# MB9BF46xx register map
File version: 1.0
CPU: 
Registers are 8-bit, read-write, reset 0x0 unless marked. A register's access mark holds for its fields unless they carry their own. Offsets are from the block's base; [hi:lo] are bit positions; {n}, {i} and the like mark numbered series; 'fields as' and 'values as' point back to an identical list.

## BTIOSEL03 — peripheral BTIOSEL03
Base 0x40025100
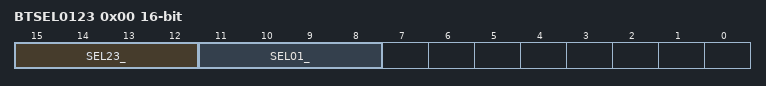
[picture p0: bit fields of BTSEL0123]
0x00 BTSEL0123 16-bit
  [15:12] SEL23_, [11:8] SEL01_

## BTIOSEL47 — peripheral BTIOSEL47
Base 0x40025300
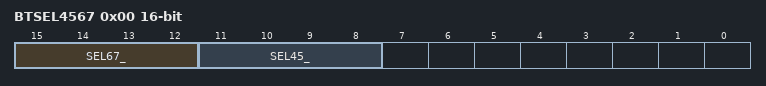
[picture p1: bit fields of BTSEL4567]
0x00 BTSEL4567 16-bit
  [15:12] SEL67_, [11:8] SEL45_

## BTIOSEL8B — peripheral BTIOSEL8B
Base 0x40025500
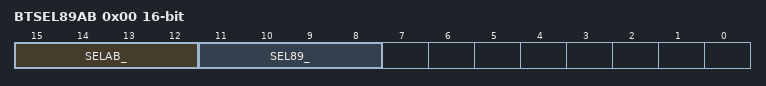
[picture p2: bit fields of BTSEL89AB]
0x00 BTSEL89AB 16-bit
  [15:12] SELAB_, [11:8] SEL89_

## BTIOSELCF — peripheral BTIOSELCF
Base 0x40025700
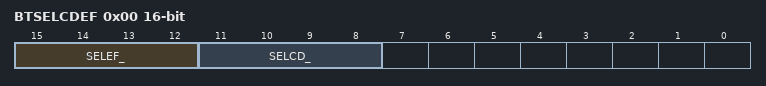
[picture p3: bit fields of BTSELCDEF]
0x00 BTSELCDEF 16-bit
  [15:12] SELEF_, [11:8] SELCD_

## SBSSR — peripheral SBSSR
Base 0x40025F00
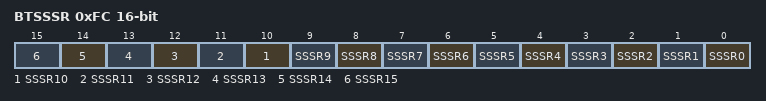
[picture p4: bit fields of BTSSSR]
0xFC BTSSSR 16-bit wo reset not defined
  [n] SSSR{n} (n=0..15)

## BT0 — peripheral BT0
Base 0x40025000
Same registers: BT1 0x40025040, BT2 0x40025080, BT3 0x400250C0, BT4 0x40025200, BT5 0x40025240, BT6 0x40025280, BT7 0x400252C0, BT8 0x40025400, BT9 0x40025440, BT10 0x40025480, BT11 0x400254C0, BT12 0x40025600, BT13 0x40025640, BT14 0x40025680, BT15 0x400256C0
0x00 PWM_PCSR 16-bit reset not defined (PWM view)
0x00 PPG_PRLL 16-bit reset not defined (PPG view)
0x00 RT_PCSR 16-bit reset not defined (RT view)
0x04 PWM_PDUT 16-bit reset not defined (PWM view)
0x04 PPG_PRLH 16-bit reset not defined (PPG view)
0x04 PWC_DTBF 16-bit ro (PWC view)
0x08 PWM_TMR 16-bit ro (PWM view)
0x08 PPG_TMR 16-bit ro (PPG view)
0x08 RT_TMR 16-bit ro reset not defined (RT view)
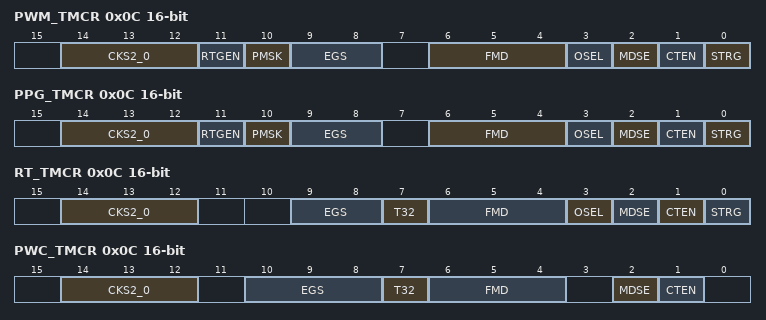
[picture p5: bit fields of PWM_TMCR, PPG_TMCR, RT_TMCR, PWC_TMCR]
0x0C PWM_TMCR 16-bit (PWM view)
  [14:12] CKS2_0, [11] RTGEN, [10] PMSK, [9:8] EGS, [6:4] FMD, [3] OSEL, [2] MDSE, [1] CTEN, [0] STRG
0x0C PPG_TMCR 16-bit (PPG view)
  fields as PWM_TMCR
0x0C RT_TMCR 16-bit (RT view)
  [14:12] CKS2_0, [9:8] EGS, [7] T32, [6:4] FMD, [3] OSEL, [2] MDSE, [1] CTEN, [0] STRG
0x0C PWC_TMCR 16-bit (PWC view)
  [14:12] CKS2_0, [10:8] EGS, [7] T32, [6:4] FMD, [2] MDSE, [1] CTEN
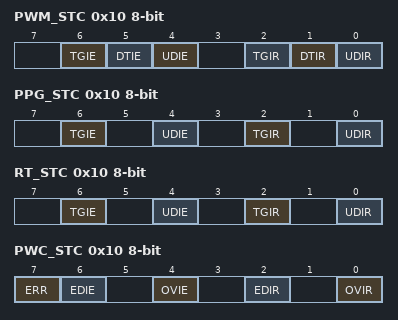
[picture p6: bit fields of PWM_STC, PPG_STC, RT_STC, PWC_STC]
0x10 PWM_STC (PWM view)
  [6] TGIE, [5] DTIE, [4] UDIE, [2] TGIR, [1] DTIR, [0] UDIR
0x10 PPG_STC (PPG view)
  [6] TGIE, [4] UDIE, [2] TGIR, [0] UDIR
0x10 RT_STC (RT view)
  [6] TGIE, [4] UDIE, [2] TGIR, [0] UDIR
0x10 PWC_STC (PWC view)
  [7] ERR ro, [6] EDIE, [4] OVIE, [2] EDIR ro, [0] OVIR
0x11 PWM_TMCR2 (PWM view)
  [0] CKS3
0x11 PPG_TMCR2 (reset mask 0x1) (PPG view)
  [1] CKS3
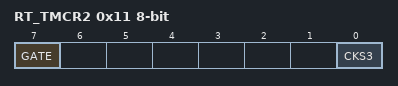
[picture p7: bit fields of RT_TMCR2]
0x11 RT_TMCR2 (RT view)
  [7] GATE, [0] CKS3
0x11 PWC_TMCR2 (PWC view)
  [0] CKS3

## QPRC0 — peripheral QPRC0
Base 0x40026000
Same registers: QPRC1 0x40026040, QPRC2 0x40026080, QPRC3 0x400260C0
0x00 QPCR 16-bit
0x04 QRCR 16-bit
0x08 QPCCR 16-bit
0x0C QPRCR 16-bit
0x10 QMPR 16-bit reset 0xFFFF
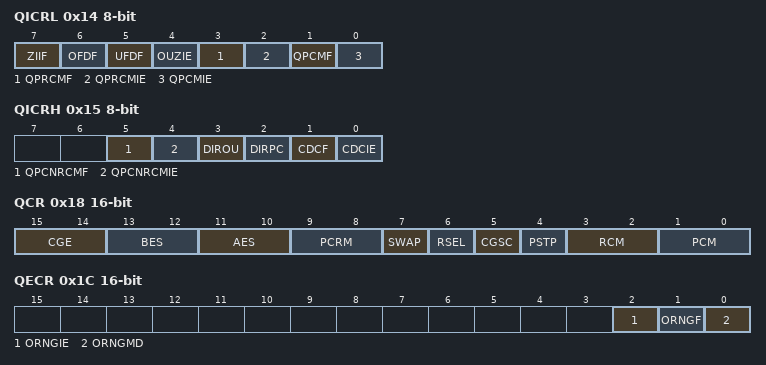
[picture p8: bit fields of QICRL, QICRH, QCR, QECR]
0x14 QICRL
  [7] ZIIF, [6] OFDF, [5] UFDF, [4] OUZIE, [3] QPRCMF, [2] QPRCMIE, [1] QPCMF, [0] QPCMIE
0x15 QICRH
  [5] QPCNRCMF, [4] QPCNRCMIE, [3] DIROU ro, [2] DIRPC ro, [1] CDCF, [0] CDCIE
0x18 QCR 16-bit
  [15:14] CGE, [13:12] BES, [11:10] AES, [9:8] PCRM, [7] SWAP, [6] RSEL, [5] CGSC, [4] PSTP, [3:2] RCM, [1:0] PCM
0x1C QECR 16-bit
  [2] ORNGIE, [1] ORNGF, [0] ORNGMD
0x3C QRCRR 16-bit
0x3E QPCRR 16-bit

## QPRC0_NF — peripheral QPRC0_NF
Base 0x40026100
Same registers: QPRC1_NF 0x40026110, QPRC2_NF 0x40026120, QPRC3_NF 0x40026130
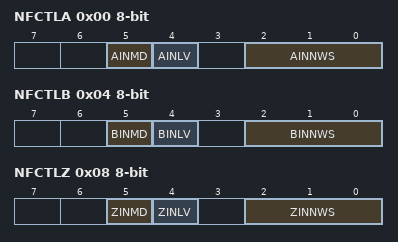
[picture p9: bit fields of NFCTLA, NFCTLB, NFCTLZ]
0x00 NFCTLA
  [5] AINMD, [4] AINLV, [2:0] AINNWS
0x04 NFCTLB
  [5] BINMD, [4] BINLV, [2:0] BINNWS
0x08 NFCTLZ
  [5] ZINMD, [4] ZINLV, [2:0] ZINNWS

## ADC0 — peripheral ADC0
Base 0x40027000
Same registers: ADC1 0x40027100, ADC2 0x40027200
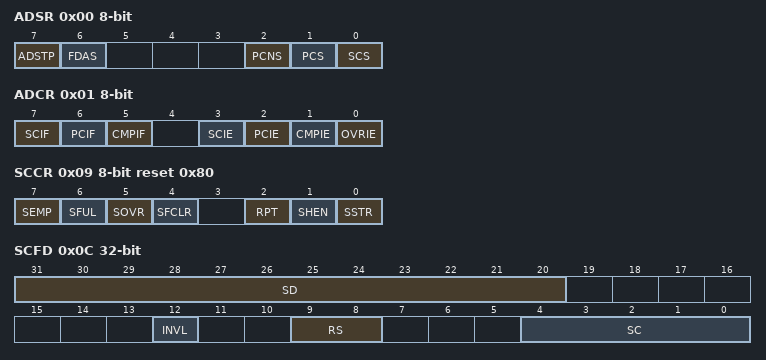
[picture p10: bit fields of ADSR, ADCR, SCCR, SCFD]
0x00 ADSR
  [7] ADSTP, [6] FDAS, [2] PCNS, [1] PCS, [0] SCS
0x01 ADCR
  [7] SCIF, [6] PCIF, [5] CMPIF, [3] SCIE, [2] PCIE, [1] CMPIE, [0] OVRIE
0x08 SFNS
  [3:0] SFS
0x09 SCCR reset 0x80
  [7] SEMP ro, [6] SFUL ro, [5] SOVR, [4] SFCLR, [2] RPT, [1] SHEN, [0] SSTR
0x0C SCFD 32-bit ro
  [31:20] SD, [12] INVL, [9:8] RS, [4:0] SC
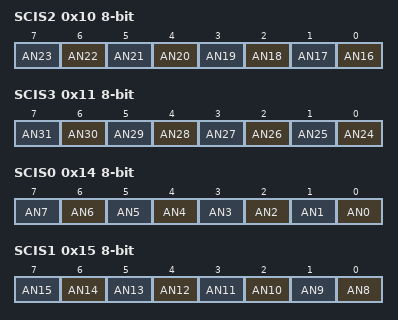
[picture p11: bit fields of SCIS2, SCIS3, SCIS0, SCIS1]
0x10 SCIS2
  [n-16] AN{n} (n=16..23)
0x11 SCIS3
  [n-24] AN{n} (n=24..31)
0x14 SCIS0
  [n] AN{n} (n=0..7)
0x15 SCIS1
  [n-8] AN{n} (n=8..15)
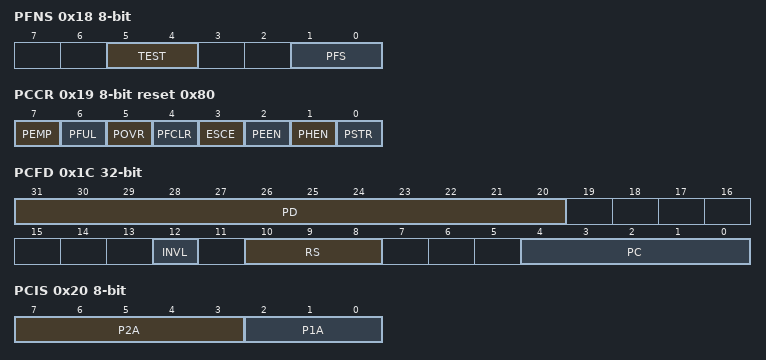
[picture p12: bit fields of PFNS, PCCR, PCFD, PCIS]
0x18 PFNS
  [5:4] TEST ro, [1:0] PFS
0x19 PCCR reset 0x80
  [7] PEMP ro, [6] PFUL ro, [5] POVR, [4] PFCLR, [3] ESCE, [2] PEEN, [1] PHEN, [0] PSTR
0x1C PCFD 32-bit ro
  [31:20] PD, [12] INVL, [10:8] RS, [4:0] PC
0x20 PCIS
  [7:3] P2A, [2:0] P1A
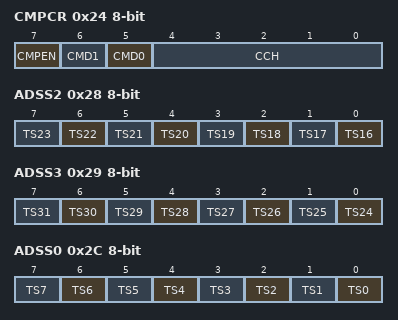
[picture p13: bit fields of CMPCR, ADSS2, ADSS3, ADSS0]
0x24 CMPCR
  [7] CMPEN, [6] CMD1, [5] CMD0, [4:0] CCH
0x26 CMPD 16-bit
  [15:6] CMAD
0x28 ADSS2
  [n-16] TS{n} (n=16..23)
0x29 ADSS3
  [n-24] TS{n} (n=24..31)
0x2C ADSS0
  [n] TS{n} (n=0..7)
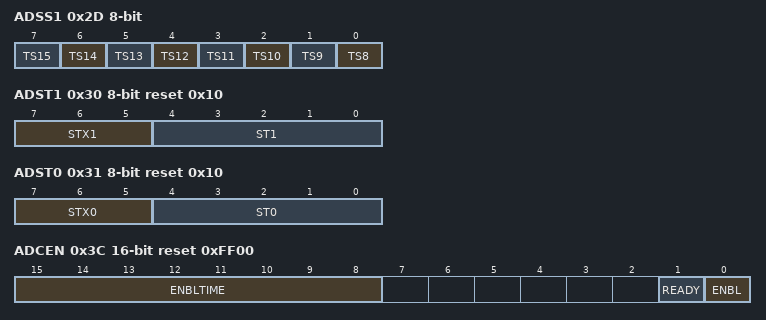
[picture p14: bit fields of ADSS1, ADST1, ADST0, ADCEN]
0x2D ADSS1
  [n-8] TS{n} (n=8..15)
0x30 ADST1 reset 0x10
  [7:5] STX1, [4:0] ST1
0x31 ADST0 reset 0x10
  [7:5] STX0, [4:0] ST0
0x34 ADCT reset 0x7 (reset mask 0x7)
  [7:0] CT
0x38 PRTSL
  [3:0] PRTSL
0x39 SCTSL
  [3:0] SCTSL
0x3C ADCEN 16-bit reset 0xFF00
  [15:8] ENBLTIME, [1] READY ro, [0] ENBL
0x44 WCMRCOT
  [0] RCOOF
0x48 WCMRCIF
  [0] RCINT
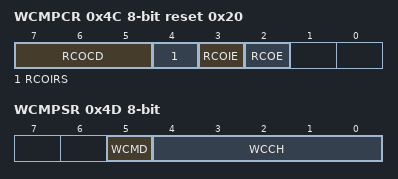
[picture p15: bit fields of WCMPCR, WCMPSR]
0x4C WCMPCR reset 0x20
  [7:5] RCOCD, [4] RCOIRS, [3] RCOIE, [2] RCOE
0x4D WCMPSR
  [5] WCMD, [4:0] WCCH
0x50 WCMPDL 16-bit
  [15:6] CMLD
0x52 WCMPDH 16-bit
  [15:6] CMHD
